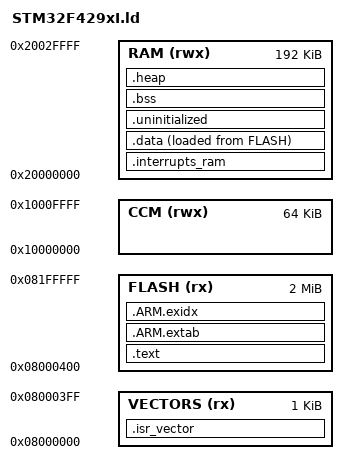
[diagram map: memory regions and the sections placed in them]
M_VECTOR_RAM_SIZE = 0x400;

/* With the RTOS in use, this does not affect the main stack size. The size of
 * the stack where main runs is determined via the RTOS. */
STACK_SIZE = 0x400;

HEAP_SIZE = 0x6000;

#if !defined(MBED_APP_START)
  #define MBED_APP_START 0x08000000
#endif

#if !defined(MBED_APP_SIZE)
  #define MBED_APP_SIZE 2048k
#endif

/* Specify the memory areas */
MEMORY
{
    VECTORS (rx) : ORIGIN = MBED_APP_START, LENGTH = 0x400
    FLASH (rx)   : ORIGIN = MBED_APP_START + 0x400, LENGTH = MBED_APP_SIZE - 0x400
    CCM (rwx)    : ORIGIN = 0x10000000, LENGTH = 64K
    RAM (rwx)    : ORIGIN = 0x20000000, LENGTH = 192k
}

/* Linker script to place sections and symbol values. Should be used together
 * with other linker script that defines memory regions FLASH and RAM.
 * It references following symbols, which must be defined in code:
 *   Reset_Handler : Entry of reset handler
 *
 * It defines following symbols, which code can use without definition:
 *   __exidx_start
 *   __exidx_end
 *   __etext
 *   __data_start__
 *   __preinit_array_start
 *   __preinit_array_end
 *   __init_array_start
 *   __init_array_end
 *   __fini_array_start
 *   __fini_array_end
 *   __data_end__
 *   __bss_start__
 *   __bss_end__
 *   __end__
 *   end
 *   __HeapLimit
 *   __StackLimit
 *   __StackTop
 *   __stack
 *   _estack
 */
ENTRY(Reset_Handler)

SECTIONS
{
    .isr_vector :
    {
        __vector_table = .;
        KEEP(*(.isr_vector))
         . = ALIGN(8);
    } > VECTORS

    .text :
    {

        *(.text*)

        KEEP(*(.init))
        KEEP(*(.fini))

        /* .ctors */
        *crtbegin.o(.ctors)
        *crtbegin?.o(.ctors)
        *(EXCLUDE_FILE(*crtend?.o *crtend.o) .ctors)
        *(SORT(.ctors.*))
        *(.ctors)

        /* .dtors */
        *crtbegin.o(.dtors)
        *crtbegin?.o(.dtors)
        *(EXCLUDE_FILE(*crtend?.o *crtend.o) .dtors)
        *(SORT(.dtors.*))
        *(.dtors)

        *(.rodata*)

        KEEP(*(.eh_frame*))
    } > FLASH

    .ARM.extab :
    {
        *(.ARM.extab* .gnu.linkonce.armextab.*)
    } > FLASH

    __exidx_start = .;

    .ARM.exidx :
    {
        *(.ARM.exidx* .gnu.linkonce.armexidx.*)
    } > FLASH
    __exidx_end = .;

    __etext = .;
    _sidata = .;

    .interrupts_ram :
    {
        . = ALIGN(8);
        __VECTOR_RAM__ = .;
        __interrupts_ram_start__ = .; /* Create a global symbol at data start */
        *(.m_interrupts_ram)     /* This is a user defined section */
        . += M_VECTOR_RAM_SIZE;
        . = ALIGN(8);
        __interrupts_ram_end__ = .; /* Define a global symbol at data end */
    } > RAM


    .data :
    {
        PROVIDE( __etext = LOADADDR(.data) );

        __data_start__ = .;
        _sdata = .;
        *(vtable)
        *(.data*)

        . = ALIGN(8);
        /* preinit data */
        PROVIDE_HIDDEN (__preinit_array_start = .);
        KEEP(*(.preinit_array))
        PROVIDE_HIDDEN (__preinit_array_end = .);

        . = ALIGN(8);
        /* init data */
        PROVIDE_HIDDEN (__init_array_start = .);
        KEEP(*(SORT(.init_array.*)))
        KEEP(*(.init_array))
        PROVIDE_HIDDEN (__init_array_end = .);


        . = ALIGN(8);
        /* finit data */
        PROVIDE_HIDDEN (__fini_array_start = .);
        KEEP(*(SORT(.fini_array.*)))
        KEEP(*(.fini_array))
        PROVIDE_HIDDEN (__fini_array_end = .);

        KEEP(*(.jcr*))
        . = ALIGN(8);
        /* All data end */
        __data_end__ = .;
        _edata = .;

    } > RAM AT > FLASH


    /* Uninitialized data section
     * This region is not initialized by the C/C++ library and can be used to
     * store state across soft reboots. */
    .uninitialized (NOLOAD):
    {
        . = ALIGN(32);
        __uninitialized_start = .;
        *(.uninitialized)
        KEEP(*(.keep.uninitialized))
        . = ALIGN(32);
        __uninitialized_end = .;
    } > RAM

    .bss (NOLOAD):
    {
        . = ALIGN(8);
        __bss_start__ = .;
        _sbss = .;
        *(.bss*)
        *(COMMON)
        . = ALIGN(8);
        __bss_end__ = .;
        _ebss = .;
    } > RAM

    .heap (NOLOAD):
    {
        __end__ = .;
        end = __end__;
        . += HEAP_SIZE;
        __HeapLimit = .;
    } > RAM

    __StackTop = ORIGIN(RAM) + LENGTH(RAM);
    __stack = __StackTop;
    __StackLimit = __StackTop - STACK_SIZE;

    ASSERT(__StackLimit >= __HeapLimit, "Region RAM overflowed with stack and heap")

}
